VERSION "nissan_frontier_2015_candidate - derived from opendbc/nissan_xterra_2011.dbc (same F-Alpha platform). Signals marked CANDIDATE need on-vehicle validation."

NS_ :

BS_:

BU_ XXX

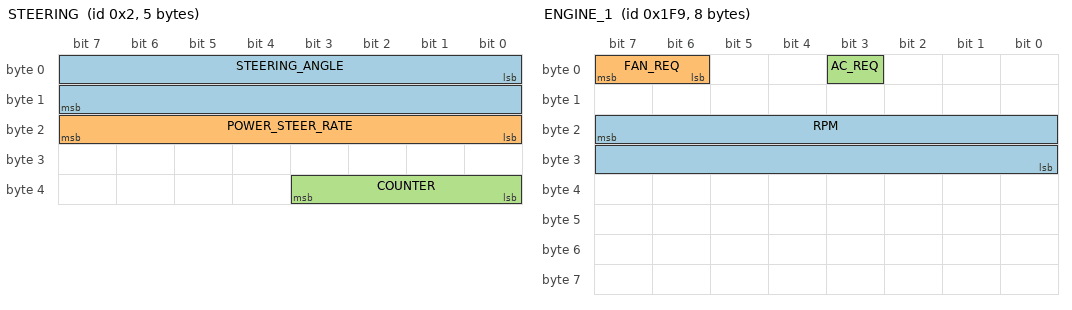
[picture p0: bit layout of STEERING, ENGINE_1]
BO_ 2 STEERING: 5 XXX
 SG_ STEERING_ANGLE : 0|16@1- (0.1,0) [-3276.8|3276.7] "deg" XXX
 SG_ POWER_STEER_RATE : 23|8@0+ (1,0) [0|255] "" XXX
 SG_ COUNTER : 35|4@0+ (1,0) [0|15] "" XXX

BO_ 352 THROTTLE: 7 XXX
 SG_ THROTTLE_POSITION : 24|8@1+ (0.392,0) [0|100] "%" XXX
 SG_ THROTTLE_POSITION_INV : 40|8@1+ (-0.392,99.96) [0|100] "%" XXX

BO_ 384 ENGINE_RPM_ALT: 8 XXX
 SG_ RPM : 7|16@0+ (0.125,0) [0|8191.875] "rpm" XXX

BO_ 505 ENGINE_1: 8 XXX
 SG_ RPM : 23|16@0+ (0.125,0) [0|8191.875] "rpm" XXX
 SG_ FAN_REQ : 6|2@1+ (1,0) [0|3] "" XXX
 SG_ AC_REQ : 3|1@1+ (1,0) [0|1] "" XXX

BO_ 640 SPEED: 8 XXX
 SG_ SPEED : 39|16@0+ (0.01,0) [0|655.35] "mph" XXX

BO_ 644 ABS_1: 8 XXX
 SG_ WHEEL_1 : 7|16@0+ (0.01,0) [0|655.35] "km/h" XXX
 SG_ WHEEL_2 : 23|16@0+ (0.01,0) [0|655.35] "km/h" XXX

BO_ 645 ABS_2: 8 XXX
 SG_ WHEEL_3 : 7|16@0+ (0.01,0) [0|655.35] "km/h" XXX
 SG_ WHEEL_4 : 23|16@0+ (0.01,0) [0|655.35] "km/h" XXX

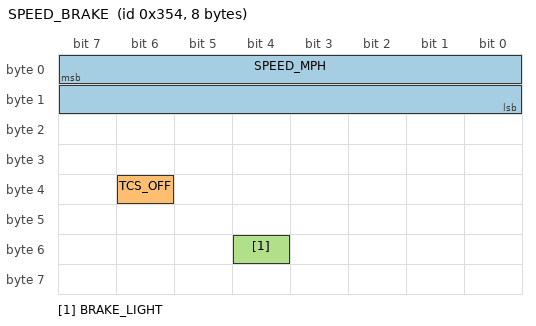
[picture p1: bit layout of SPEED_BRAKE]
BO_ 852 SPEED_BRAKE: 8 XXX
 SG_ SPEED_MPH : 7|16@0+ (0.0066,0) [0|432.3] "mph" XXX
 SG_ TCS_OFF : 38|1@0+ (1,0) [0|1] "" XXX
 SG_ BRAKE_LIGHT : 52|1@0+ (1,0) [0|1] "" XXX

BO_ 861 BCM: 8 XXX
 SG_ BRAKE_SWITCH : 36|1@1+ (1,0) [0|1] "" XXX

BO_ 1361 ENGINE_5: 8 XXX
 SG_ COOLANT_TEMP : 0|8@1+ (1,-45) [-45|210] "degC" XXX

BO_ 1408 ENGINE_6: 8 XXX
 SG_ RPM_COARSE : 7|16@0+ (1.5,0) [0|98302.5] "rpm" XXX
 SG_ OIL_TEMP : 32|8@1+ (1,-40) [-40|215] "degC" XXX

BO_ 375 SHIFT_TORQUE_REQ: 8 XXX
 SG_ TORQUE_REDUCE_REQ : 32|8@1+ (1,0) [0|255] "" XXX

BO_ 386 ENGINE_TORQUE: 8 XXX
 SG_ ENGINE_TORQUE : 32|8@1+ (1,0) [0|255] "" XXX

BO_ 1057 GEARBOX: 3 XXX
 SG_ GEAR_SELECTOR : 0|8@1+ (1,0) [0|32] "" XXX

BO_ 1477 MILEAGE: 8 XXX

CM_ SG_ 505 RPM "CONFIRMED on-vehicle: big-endian (Motorola), 0.125 rpm/bit. Idle raw ~5650 = ~706 rpm. NOTE: Xterra DBC had this little-endian, which is WRONG for the Frontier.";
CM_ SG_ 384 RPM "CONFIRMED: same RPM value mirrored here in bytes 0-1, big-endian.";
CM_ SG_ 2 STEERING_ANGLE "CONFIRMED on-vehicle: little-endian signed, 0.1 deg/bit, offset 0. Reads ~0 centered; swept -613..+611 deg. (Endianness is per-signal here: RPM is big-endian, this is little-endian.)";
CM_ SG_ 352 THROTTLE_POSITION "CONFIRMED (discovery, not in Xterra DBC): 0x160 byte3, 0 at idle (throttle closed), rises with pedal blips and leads RPM. Scale 0.392 assumed (0-255=0-100%); refine at wide-open throttle.";
CM_ SG_ 352 THROTTLE_POSITION_INV "Redundant TPS track: raw byte5 = 255 - byte3. Should read same % as THROTTLE_POSITION (dual-track sensor validation). Accel PEDAL candidate also at 0x160 byte4 (idle ~8, reaches 200).";
CM_ SG_ 1361 COOLANT_TEMP "HIGH CONFIDENCE: read ~46-47 degC at idle in the baseline capture.";
CM_ SG_ 1057 GEAR_SELECTOR "CONFIRMED (discovery): 0x421 byte0. P=0x08 (baseline/park), R=0x10, N=0x18, D=0x20 (+8 each); 0x00 flickers between detents.";
CM_ SG_ 375 TORQUE_REDUCE_REQ "CONFIRMED (9 upshifts, 2026-09-11): 0x177 byte4 = TCU->ECM torque-reduction request; 0 except a ~150ms pulse at each upshift. Magnitude scales with ENGINE RPM AT THE SHIFT (rpm_pre), r=0.964 (throttle r=0.51, weaker). Range 0x0D@~1950rpm .. 0xCD@~5800rpm. GEAR-DEPENDENT (confirmed 2026-09-11 via gear inference in shift_analyze.py 3b): the request is NOT one global line -- it splits by gear-pair. G1->G2: req = 0.0442*rpm - 49.6 (r=0.997, steep). The global fit is an artifact of mixing shift types (r collapses 0.96->0.53 as gear variety is added). The 8HP70 gateway needs a PER-GEAR-PAIR map. G1->G2 LOCKED (reproduced over 2 sessions, n=6+3): req = 0.0447*rpm - 58.3 (r=0.950). G2->G3 rises more gently but scattered (n=10): ~0.019*rpm + 67 (r=0.82). G3->G4 (n=5) all req=0x4D(77) but over a narrow RPM band 3040-3500 -> flat-vs-sloped UNRESOLVED. G4->G5 still not cleanly isolated. Gear ladder rpm/mph: G1=107 G2=68 G3=44 G4=28 (G5~22). STEPPED-MAP MODEL (shift_analyze.py 3c, better than linear -- request is a quantized TCU calibration table, not a line). Observed levels (gear x RPM -> 0x177 b4), from 64 combined events (2026-09-11_torque_ALL_combined.txt): G1->G2 DONE (n=13): 0x33 @2281-2662 (step ~2809), 0x4D @2956, 0x66 @3306-3647, 0xCD @5806 (big jump up high). G2->G3 DONE (n=13): 0x53 @2130-2280, 0x80 @2420, 0x9A @3125-4831, 0xA0 @5362, 0xA7 @5806-5850. Level quantization set: {33,4D,53,66,80,9A,A0,A7,CD}. FULL MAP COMPLETE (64 events, shift_analyze.py --gears 106,68,44,28,22 imposing the clean ladder from the steady D-run, which unblocked the coasting-blurred higher gears): G1->G2: 0x33 <~2810, 0x4D ~2810-3130, 0x66 ~3130-4726, 0xCD @5800. G2->G3: 0x53 <~2350, 0x80 ~2350-2820, 0x9A ~2820-5100, 0xA0 ~5100-5580, 0xA7 >~5580. G3->G4: 0x33 <~2870, 0x4D ~2870-3645, 0x66 >~3645 (the earlier 'constant 77' was just the middle step). G4->G5: 0x00 (no reduction) at low rpm, 0x0D, 0x1A, 0x33, 0x40 >~2846. KEY PATTERN: request scales DOWN in higher gears (G4->G5 max 0x40 vs G1->G2 0xCD) -- less inertia to manage. This is the LOOKUP TABLE the 8HP70 gateway must reproduce. Remaining: confirm single-obs levels + one overlap in G4->G5 boundary.";
CM_ SG_ 386 ENGINE_TORQUE "CANDIDATE (2 upshifts): 0x182 byte4 = engine torque/load. Pegged 0xFF under hard load, dips ~50% exactly as RPM falls during the shift; rose with throttle earlier. The ECM side of the shift torque handshake. Scale raw pending.";

VAL_ 1057 GEAR_SELECTOR 8 "P" 16 "R" 24 "N" 32 "D" 0 "SHIFTING" ;
CM_ SG_ 640 SPEED "CONFIRMED on-vehicle: big-endian bytes4-5, unit is 0.01 MPH (peak raw 1091 = 10.9 mph vs driver-reported ~11 mph). Note: this is mph, while the ABS wheels below are km/h.";
CM_ SG_ 644 WHEEL_1 "CONFIRMED: 0x284/0x285 all four wheels big-endian, 0.01 km/h (peak raw 1858 = 18.6 km/h = 11.5 mph, matches ~11 mph). All four agree straight, split slightly in turns.";
CM_ SG_ 852 BRAKE_LIGHT "CONFIRMED on-vehicle: byte6 toggles 0x04<->0x14 (bit 52) on brake press.";
CM_ SG_ 861 BRAKE_SWITCH "CONFIRMED: BCM byte4 bit4 toggles 0x00<->0x10 on brake press (was an undecoded message). Candidate brake flags also at 0x180 b7 bit0 and 0x182 b6 bit6.";
